# GD32M53x register map
File version: 1.0
CPU: CM33 r2p1, little endian, MPU, FPU, DSP, 4 interrupt priority bits
Registers are 32-bit, read-write, reset 0x0 unless marked. A register's access mark holds for its fields unless they carry their own. Offsets are from the block's base; [hi:lo] are bit positions.

## FMC — Flash memory controller
Base 0x40022000
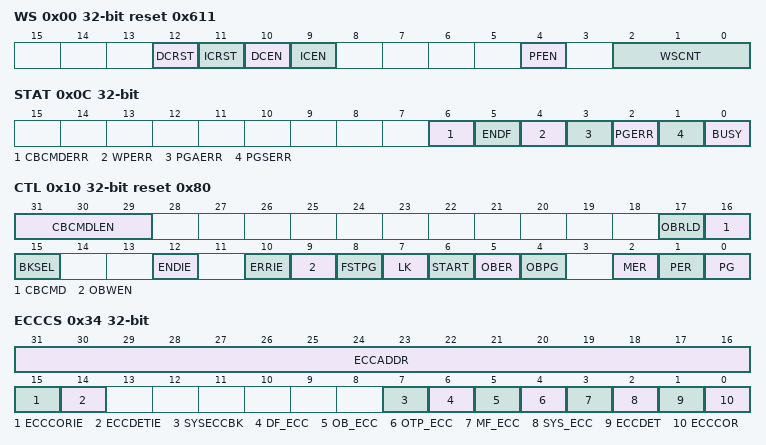
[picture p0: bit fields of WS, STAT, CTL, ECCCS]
0x00 WS reset 0x611 — Wait state register
  [12] DCRST — D-cache reset. This bit can be write only when DCEN is set to 0.
  [11] ICRST — I-cache reset. This bit can be write only when ICEN is set to 0.
  [10] DCEN — D-cache enable
  [9] ICEN — I-cache enable
  [4] PFEN — Pre-fetch enable
  [2:0] WSCNT — Wait state counter register
0x04 KEY wo — Unlock key register
  [31:0] KEY — FMC_CTL unlock register
0x08 OBKEY wo — Option byte unlock key register
  [31:0] OBKEY — FMC_CTL option bytes operation unlock register
0x0C STAT access per field — Status register
  [6] CBCMDERR rw — The checked area by the check blank command is all 0xFF or not.
  [5] ENDF rw — End of operation flag bit
  [4] WPERR rw — Erase / Program protection error flag bit
  [3] PGAERR rw — Program alignment error flag bit
  [2] PGERR rw — Program error flag bit
  [1] PGSERR rw — Programming sequence error flag bit
  [0] BUSY ro — The flash is busy bit
0x10 CTL reset 0x80 — Control register
  [31:29] CBCMDLEN — CBCMD read length 2^(CBCMDLEN).
  [17] OBRLD — Option byte reload bit
  [16] CBCMD — The command to check the selected area is blank or not.
  [15] BKSEL — Select the flash bank for the operation.
  [12] ENDIE — End of operation interrupt enable bit
  [10] ERRIE — Error interrupt enable bit
  [9] OBWEN — Option byte erase / program enable bit
  [8] FSTPG — Flash fast program command bit
  [7] LK — FMC_CTL lock bit
  [6] START — Send erase command to FMC bit
  [5] OBER — Option bytes erase command bit
  [4] OBPG — Option bytes program command bit
  [2] MER — Flash mass erase command bit
  [1] PER — Flash page erase command bit
  [0] PG — Flash program command bit
0x14 ADDR wo — Address register
  [31:0] ADDR — Flash erase / program command address bits
0x18 DATA wo — Program data register
  [31:0] DATA — Flash erase / program command DATA bits
0x34 ECCCS access per field — ECC control and status register
  [31:16] ECCADDR ro — The offset address of double word where an ECC error is detected.
  [15] ECCCORIE rw — One bit error correct interrupt enable.
  [14] ECCDETIE rw — Two bits errors detect interrupt enable.
  [7] SYSECCBK ro — This bit in read only to indicate whether the system memory ECC error occurs in the first 3k or later 3k region of the information block.
  [6] DF_ECC rw — If an ECC bit error is detected in data flash, this bit will be set. And the ECCADDR records the offset address of main Flash. ECCDET bit and ECCCOR bit indicate there is a one bit error or a two bits error. This bit is cleared by writing 1.
  [5] OB_ECC rw — If an ECC bit error is detected in reading option bytes, this bit will be set. And the ECCADDR records the offset address of option bytes. ECCDET bit and ECCCOR bit indicate there is a one bit error or a two bits error. This bit is cleared by writing 1. This bit is cleared by writing 1.
  [4] OTP_ECC rw — If an ECC bit error is detected in OTP, this bit will be set. And the ECCADDR records the offset address of OTP. ECCDET bit and ECCCOR bit indicate there is a one bit error or a two bits error. This bit is cleared by writing 1.
  [3] MF_ECC rw — If an ECC bit error is detected in main Flash, this bit will be set. And the ECCADDR records the offset address of main Flash. ECCDET bit and ECCCOR bit indicate there is a one bit error or a two bits error. This bit is cleared by writing 1.
  [2] SYS_ECC rw — If an ECC bit error is detected in system memory, this bit will be set. And the ECCADDR records the offset address of system memory. ECCDET bit and ECCCOR bit indicate there is a one bit error or a two bits error. This bit is cleared by writing 1.
  [1] ECCDET rw — Two bit errors detect flag. This bit set when two bit errors is detected.
  [0] ECCCOR rw — One bit error detected and correct flag.
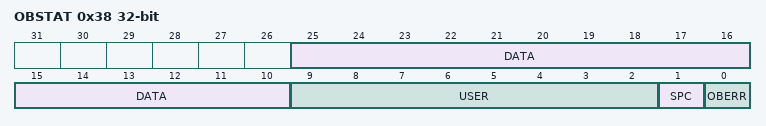
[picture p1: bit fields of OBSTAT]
0x38 OBSTAT ro — Option byte status register
  [25:10] DATA — Store DATA[15:0] of option bytes block after system reset.
  [9:2] USER — Store USER of option bytes block after system reset.
  [1] SPC — Option bytes security protection code
  [0] OBERR — Option bytes read error bit.
0x3C WP ro — Erase / Program protection register
  [31:0] WP — Store WP[31:0] of option bytes block after system reset
0x100 PID0 ro — Product ID register 0
  [31:0] PID — Product reserved ID code register
0x104 PID1 ro — Product ID register 1
  [31:0] PID — Product reserved ID code register
